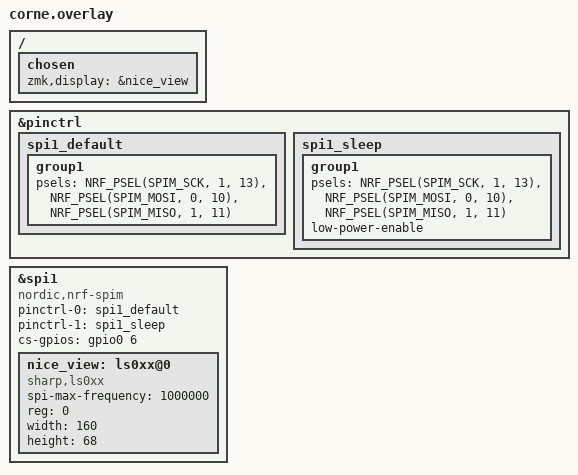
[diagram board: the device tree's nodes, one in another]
/* config/corne.overlay */

&pinctrl {
    /* Настраиваем пины для аппаратного SPI1 на nRF52840 */
    spi1_default: spi1_default {
        group1 {
            psels = <NRF_PSEL(SPIM_SCK, 1, 13)>,   /* P1.13 = SCK */
                    <NRF_PSEL(SPIM_MOSI, 0, 10)>,  /* P0.10 = MOSI */
                    <NRF_PSEL(SPIM_MISO, 1, 11)>;  /* P1.11 = MISO (не нужен, но обязателен для конфига) */
        };
    };
    spi1_sleep: spi1_sleep {
        group1 {
            psels = <NRF_PSEL(SPIM_SCK, 1, 13)>,
                    <NRF_PSEL(SPIM_MOSI, 0, 10)>,
                    <NRF_PSEL(SPIM_MISO, 1, 11)>;
            low-power-enable;
        };
    };
};

&spi1 {
    compatible = "nordic,nrf-spim";
    status = "okay";
    pinctrl-0 = <&spi1_default>;
    pinctrl-1 = <&spi1_sleep>;
    pinctrl-names = "default", "sleep";
    
    /* CS пин экрана. Обычно P0.06 на nRFMicro */
    cs-gpios = <&gpio0 6 GPIO_ACTIVE_HIGH>;

    /* Узел самого экрана. Мы добавляем его прямо в шину, без посредников */
    nice_view: ls0xx@0 {
        compatible = "sharp,ls0xx";
        spi-max-frequency = <1000000>;
        reg = <0>;
        width = <160>;
        height = <68>;
    };
};

/* Сообщаем ZMK, что этот экран нужно использовать */
/ {
    chosen {
        zmk,display = &nice_view;
    };
};
